# SGPIO4 register map
Registers from a debugger description file.
Registers are 32-bit, access not given, no defined reset value unless marked. A register's access mark holds for its fields unless they carry their own. Addresses are absolute; registers are grouped by the start of their names; lines under a group give offsets from that group; [hi:lo] are bit positions; {n}, {i} and the like mark numbered series; 'fields as' and 'values as' point back to an identical list; <NAME> marks a mode.

## SGPIO4
0x5000F000 SGPIO4/Input ro
  [31:0] Input
0x5000F004 SGPIO4/Output
  [31:0] Output
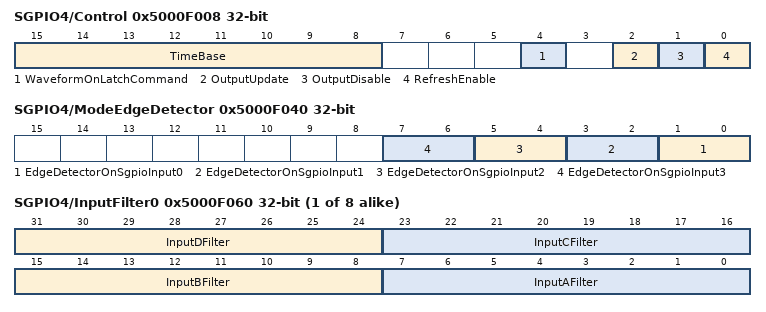
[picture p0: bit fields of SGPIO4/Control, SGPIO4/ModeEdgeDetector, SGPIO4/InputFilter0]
0x5000F008 SGPIO4/Control
  [15:8] TimeBase, [4] WaveformOnLatchCommand, [2] OutputUpdate, [1] OutputDisable, [0] RefreshEnable
0x5000F040 SGPIO4/ModeEdgeDetector
  [2n+1:2n] EdgeDetectorOnSgpioInput{n} (n=0..3)
0x5000F044 SGPIO4/StatusInt0
  [3:0] StatusInt0
0x5000F048 SGPIO4/StatusInt1
  [3:0] StatusInt1
0x5000F04C SGPIO4/MaskInt
  [3:0] MaskInt
0x5000F050 SGPIO4/ClearInt
  [3:0] ClearInt
0x5000F054 SGPIO4/InputUpdate
  [31:0] InputUpdate
{0x5000F060+4i} SGPIO4/InputFilter{i} (i=0..7)
  [31:24] InputDFilter, [23:16] InputCFilter, [15:8] InputBFilter, [7:0] InputAFilter
